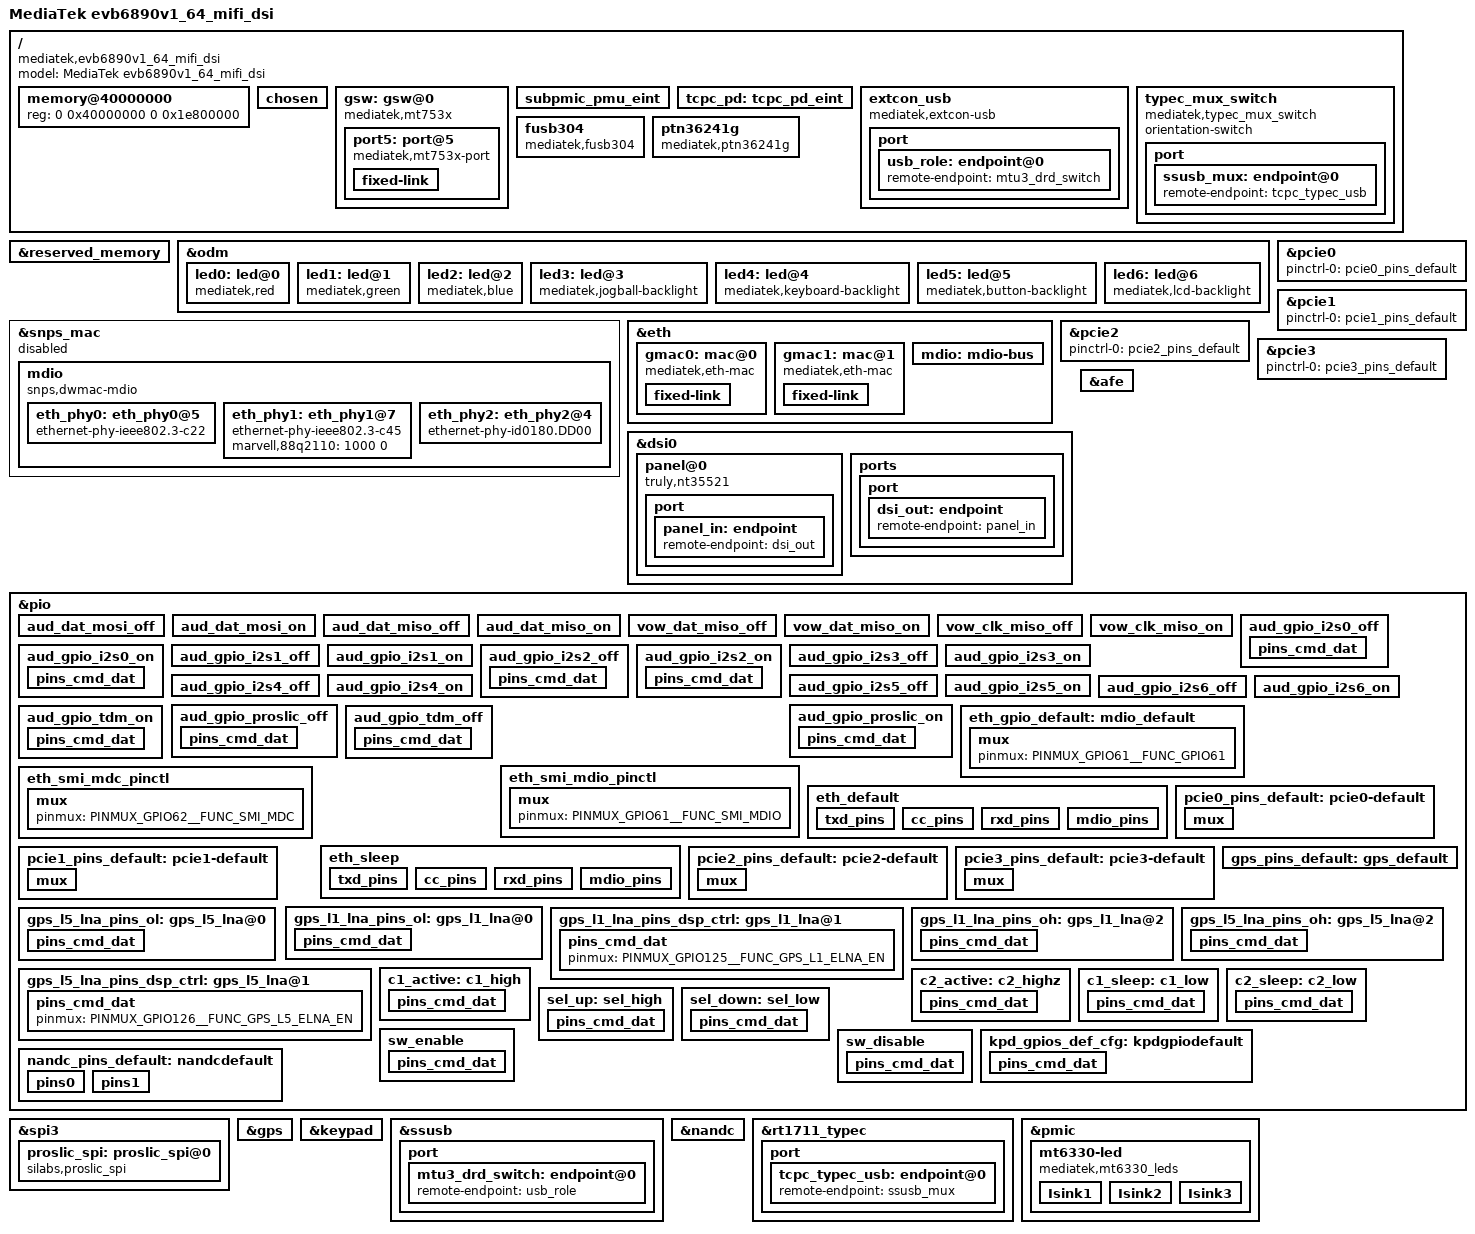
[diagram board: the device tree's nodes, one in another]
// SPDX-License-Identifier: GPL-2.0
/*
 * Copyright (c) 2019 MediaTek Inc.
 */

/dts-v1/;
#include <dt-bindings/interrupt-controller/irq.h>
#include <dt-bindings/interrupt-controller/arm-gic.h>
#include "mt6890.dtsi"
#include "tcpc_config.dtsi"
#include "rt9467.dtsi"

&reserved_memory {
};

/ {
	model = "MediaTek evb6890v1_64_mifi_dsi";
	compatible = "mediatek,evb6890v1_64_mifi_dsi", "mediatek,mt6890";

	memory@40000000 {
		device_type = "memory";
		reg = <0 0x40000000 0 0x1e800000>;
	};

	chosen {
		bootargs = "console=tty0 console=ttyS0,921600n1 \
		root=/dev/ubiblock0_0 rootfstype=squashfs ubi.mtd=28 \
		init=/etc/preinit \
		loglevel=8 \
		androidboot.selinux=permissive androidboot.hardware=mt6890 \
		initcall_debug=1 page_owner=on";

		atag,videolfb-fb_base_l = <0x7e605000>;
		atag,videolfb-fb_base_h = <0x0>;
		atag,videolfb-islcmfound = <1>;
		atag,videolfb-islcm_inited = <0>;
		atag,videolfb-fps= <6000>;
		atag,videolfb-vramSize= <0x1be0000>;
		atag,videolfb-lcmname=
			"nt35595_fhd_dsi_cmd_truly_nt50358_drv";
	};

	gsw: gsw@0 {
		compatible = "mediatek,mt753x";
		mediatek,ethsys = <&ethsys>;
		#address-cells = <1>;
		#size-cells = <0>;
	};

	subpmic_pmu_eint: subpmic_pmu_eint {
	};

	tcpc_pd: tcpc_pd_eint {
	};

    extcon_usb: extcon_usb {
		compatible = "mediatek,extcon-usb";
		vbus-supply = <&otg_vbus>;
		vbus-volt = <5000000>;
		charger = <&rt9467_chg>;
		/*mediatek,bypss-typec-sink = <1>;*/
		vbus-current = <1800000>;
		port {
			usb_role: endpoint@0 {
				remote-endpoint = <&mtu3_drd_switch>;
			};
		};
	};

    typec_mux_switch: typec_mux_switch {
		compatible = "mediatek,typec_mux_switch";
		status = "okay";
		orientation-switch;
		port {
			ssusb_mux: endpoint@0 {
				remote-endpoint = <&tcpc_typec_usb>;
			};
		};
	};

    fusb304: fusb304 {
        compatible = "mediatek,fusb304";
        pinctrl-names = "sel_up", "sel_down",
            "enable", "disable";
        pinctrl-0 = <&sel_up>;
        pinctrl-1 = <&sel_down>;
        pinctrl-2 = <&sw_enable>;
        pinctrl-3 = <&sw_disable>;
        status = "okay";
    };

    ptn36241g: ptn36241g {
        compatible = "mediatek,ptn36241g";
        pinctrl-names = "c1_active", "c1_sleep",
            "c2_active", "c2_sleep";
        pinctrl-0 = <&c1_active>;
        pinctrl-1 = <&c1_sleep>;
        pinctrl-2 = <&c2_active>;
        pinctrl-3 = <&c2_sleep>;
        status = "okay";
    };
};

&odm {
    led0:led@0 {
        compatible = "mediatek,red";
        led_mode = <0>;
        data = <1>;
        pwm_config = <0 0 0 0 0>;
    };
    led1:led@1 {
        compatible = "mediatek,green";
        led_mode = <0>;
        data = <1>;
        pwm_config = <0 0 0 0 0>;
    };
    led2:led@2 {
        compatible = "mediatek,blue";
        led_mode = <0>;
        data = <1>;
        pwm_config = <0 0 0 0 0>;
    };
    led3:led@3 {
        compatible = "mediatek,jogball-backlight";
        led_mode = <0>;
        data = <1>;
        pwm_config = <0 0 0 0 0>;
    };
    led4:led@4 {
        compatible = "mediatek,keyboard-backlight";
        led_mode = <0>;
        data = <1>;
        pwm_config = <0 0 0 0 0>;
    };
    led5:led@5 {
        compatible = "mediatek,button-backlight";
        led_mode = <0>;
        data = <1>;
        pwm_config = <0 0 0 0 0>;
    };
    led6:led@6 {
        compatible = "mediatek,lcd-backlight";
        led_mode = <5>;
        data = <1>;
        pwm_config = <0 1 0 0 0>;
    };
};

&snps_mac {
	phy-mode ="rgmii-rxid";
	phy-handle = <&eth_phy0>;
	status = "disable";
	pinctrl-names = "default", "sleep";
	pinctrl-0 = <&eth_default>;
	pinctrl-1 = <&eth_sleep>;
	snps,reset-gpio = <&pio 24 GPIO_ACTIVE_LOW>;
	snps,reset-active-low;
	mdio {
		compatible = "snps,dwmac-mdio";
		#address-cells = <1>;
		#size-cells = <0>;
		eth_phy0: eth_phy0@5 {
			compatible = "ethernet-phy-ieee802.3-c22";
		};
		eth_phy1: eth_phy1@7 {
			compatible = "ethernet-phy-ieee802.3-c45";
			marvell,88q2110 = <1000 0>;
		};
		eth_phy2: eth_phy2@4 {
			compatible = "ethernet-phy-id0180.DD00";
		};
	};
};


&eth {
	pinctrl-names = "eth_gpio_default",
		"eth_smi_mdio_pinctl",
		"eth_smi_mdc_pinctl";
	pinctrl-0 = <&eth_gpio_default>;
	pinctrl-1 = <&eth_smi_mdio_pinctl>;
	pinctrl-2 = <&eth_smi_mdc_pinctl>;
	status = "okay";
	gmac0: mac@0 {
		compatible = "mediatek,eth-mac";
		reg = <0>;
		phy-mode = "2500base-x";
		fixed-link {
			speed = <2500>;
			full-duplex;
			pause;
		};
	};
	gmac1: mac@1 {
		compatible = "mediatek,eth-mac";
		reg = <1>;
		phy-mode = "2500base-x";
		fixed-link {
			speed = <2500>;
			full-duplex;
			pause;
		};
	};
	mdio: mdio-bus {
		#address-cells = <1>;
		#size-cells = <0>;
	};
};

&gsw {
	mediatek,mdio = <&mdio>;
	mediatek,portmap = "llllw";
	mediatek,mdio_master_pinmux = <0>;
	reset-gpios = <&pio 66 0>;
	interrupt-parent = <&pio>;
	interrupts = <65 IRQ_TYPE_LEVEL_HIGH>;

	status = "okay";

	port5: port@5 {
		compatible = "mediatek,mt753x-port";
		reg = <5>;
		phy-mode = "sgmii";
		fixed-link {
			speed = <2500>;
			full-duplex;
		};
	};
};

&pcie0 {
	pinctrl-names = "default";
	pinctrl-0 = <&pcie0_pins_default>;
	status = "okay";
};

&pcie1 {
	pinctrl-names = "default";
	pinctrl-0 = <&pcie1_pins_default>;
	status = "okay";
};

&pcie2 {
	pinctrl-names = "default";
	pinctrl-0 = <&pcie2_pins_default>;
	status = "okay";
};

&pcie3 {
	pinctrl-names = "default";
	pinctrl-0 = <&pcie3_pins_default>;
	status = "okay";
};

/*
&odm {
	vibrator0:vibrator@0 {
		compatible = "mediatek,vibrator";
		vib_timer = <25>;
		vib_limit = <9>;
		vib_vol= <9>;
	};
};*/

&dsi0 {
	status = "okay";
	#address-cells = <1>;
	#size-cells = <0>;
	panel@0 {
		compatible = "truly,nt35521";
		reg = <0>;
		pm-enable-gpios = <&pio 8 0>;
		reset-gpios = <&pio 208 0>;
		bias-gpios = <&pio 10 0>,
			<&pio 10 0>;
		pinctrl-names = "default";
		port {
			panel_in: endpoint {
				remote-endpoint = <&dsi_out>;
			};
		};
	};
	ports {
		port {
			dsi_out: endpoint {
				remote-endpoint = <&panel_in>;
			};
		};
	};
};

/* AUDIO GPIO standardization */
&afe {
	pinctrl-names = "aud_dat_miso_off", "aud_dat_miso_on",
			"aud_dat_mosi_off", "aud_dat_mosi_on",
			"aud_gpio_i2s0_off", "aud_gpio_i2s0_on",
			"aud_gpio_i2s1_off", "aud_gpio_i2s1_on",
			"aud_gpio_i2s2_off", "aud_gpio_i2s2_on",
			"aud_gpio_i2s3_off", "aud_gpio_i2s3_on",
			"aud_gpio_i2s4_off", "aud_gpio_i2s4_on",
			"aud_gpio_i2s5_off", "aud_gpio_i2s5_on",
			"aud_gpio_i2s6_off", "aud_gpio_i2s6_on",
			"vow_dat_miso_off", "vow_dat_miso_on",
			"vow_clk_miso_off", "vow_clk_miso_on",
			"aud_gpio_proslic_off", "aud_gpio_proslic_on",
			"aud_gpio_tdm_off", "aud_gpio_tdm_on";
	pinctrl-0 = <&aud_dat_mosi_off>;
	pinctrl-1 = <&aud_dat_mosi_on>;
	pinctrl-2 = <&aud_dat_miso_off>;
	pinctrl-3 = <&aud_dat_miso_on>;
	pinctrl-4 = <&aud_gpio_i2s0_off>;
	pinctrl-5 = <&aud_gpio_i2s0_on>;
	pinctrl-6 = <&aud_gpio_i2s1_off>;
	pinctrl-7 = <&aud_gpio_i2s1_on>;
	pinctrl-8 = <&aud_gpio_i2s2_off>;
	pinctrl-9 = <&aud_gpio_i2s2_on>;
	pinctrl-10 = <&aud_gpio_i2s3_off>;
	pinctrl-11 = <&aud_gpio_i2s3_on>;
	pinctrl-12 = <&aud_gpio_i2s4_off>;
	pinctrl-13 = <&aud_gpio_i2s4_on>;
	pinctrl-14 = <&aud_gpio_i2s5_off>;
	pinctrl-15 = <&aud_gpio_i2s5_on>;
	pinctrl-16 = <&aud_gpio_i2s6_off>;
	pinctrl-17 = <&aud_gpio_i2s6_on>;
	pinctrl-18 = <&vow_dat_miso_off>;
	pinctrl-19 = <&vow_dat_miso_on>;
	pinctrl-20 = <&vow_clk_miso_off>;
	pinctrl-21 = <&vow_clk_miso_on>;
	pinctrl-22 = <&aud_gpio_proslic_off>;
	pinctrl-23 = <&aud_gpio_proslic_on>;
	pinctrl-24 = <&aud_gpio_tdm_off>;
	pinctrl-25 = <&aud_gpio_tdm_on>;
	status = "okay";
};

&pio {
	/* set audio pinctrl status */
	aud_dat_mosi_off: aud_dat_mosi_off {
	};
	aud_dat_mosi_on: aud_dat_mosi_on {
	};
	aud_dat_miso_off: aud_dat_miso_off {
	};
	aud_dat_miso_on: aud_dat_miso_on {
	};
	vow_dat_miso_off: vow_dat_miso_off {
	};
	vow_dat_miso_on: vow_dat_miso_on {
	};
	vow_clk_miso_off: vow_clk_miso_off {
	};
	vow_clk_miso_on: vow_clk_miso_on {
	};
	aud_gpio_i2s0_off: aud_gpio_i2s0_off {
		pins_cmd_dat {
			pinmux = <PINMUX_GPIO230__FUNC_GPIO230>,
				 <PINMUX_GPIO231__FUNC_GPIO231>,
				 <PINMUX_GPIO232__FUNC_GPIO232>,
				 <PINMUX_GPIO233__FUNC_GPIO233>,
				 <PINMUX_GPIO234__FUNC_GPIO234>;
		};
	};
	aud_gpio_i2s0_on: aud_gpio_i2s0_on {
		pins_cmd_dat {
			pinmux = <PINMUX_GPIO230__FUNC_I2S0_MCK>,
				 <PINMUX_GPIO231__FUNC_I2S0_BCK>,
				 <PINMUX_GPIO232__FUNC_I2S0_LRCK>,
				 <PINMUX_GPIO233__FUNC_I2S0_DI>,
				 <PINMUX_GPIO234__FUNC_I2S0_DO>;
		};
	};
	aud_gpio_i2s1_off: aud_gpio_i2s1_off {
	};
	aud_gpio_i2s1_on: aud_gpio_i2s1_on {
	};
	aud_gpio_i2s2_off: aud_gpio_i2s2_off {
		pins_cmd_dat {
			pinmux = <PINMUX_GPIO91__FUNC_GPIO91>,
				 <PINMUX_GPIO92__FUNC_GPIO92>,
				 <PINMUX_GPIO93__FUNC_GPIO93>,
				 <PINMUX_GPIO94__FUNC_GPIO94>;
		};
	};
	aud_gpio_i2s2_on: aud_gpio_i2s2_on {
		pins_cmd_dat {
			pinmux = <PINMUX_GPIO91__FUNC_I2S2_MCK>,
				 <PINMUX_GPIO92__FUNC_I2S2_BCK>,
				 <PINMUX_GPIO93__FUNC_I2S2_LRCK>,
				 <PINMUX_GPIO94__FUNC_I2S2_DI>;
		};
	};
	aud_gpio_i2s3_off: aud_gpio_i2s3_off {
	};
	aud_gpio_i2s3_on: aud_gpio_i2s3_on {
	};
	aud_gpio_i2s4_off: aud_gpio_i2s4_off {
	};
	aud_gpio_i2s4_on: aud_gpio_i2s4_on {
	};
	aud_gpio_i2s5_off: aud_gpio_i2s5_off {
	};
	aud_gpio_i2s5_on: aud_gpio_i2s5_on {
	};
	aud_gpio_i2s6_off: aud_gpio_i2s6_off {
	};
	aud_gpio_i2s6_on: aud_gpio_i2s6_on {
	};

	aud_gpio_proslic_off: aud_gpio_proslic_off {
		pins_cmd_dat {
			pinmux = <PINMUX_GPIO231__FUNC_GPIO231>,
				 <PINMUX_GPIO232__FUNC_GPIO232>,
				 <PINMUX_GPIO233__FUNC_GPIO233>,
				 <PINMUX_GPIO234__FUNC_GPIO234>;
		};
	};
	aud_gpio_proslic_on: aud_gpio_proslic_on {
		pins_cmd_dat {
			pinmux = <PINMUX_GPIO231__FUNC_PCM1_CLK>,
				 <PINMUX_GPIO232__FUNC_PCM1_SYNC>,
				 <PINMUX_GPIO233__FUNC_PCM1_DI>,
				 <PINMUX_GPIO234__FUNC_PCM1_DO>;
		};
	};
	aud_gpio_tdm_off: aud_gpio_tdm_off {
		pins_cmd_dat {
			pinmux = <PINMUX_GPIO199__FUNC_GPIO199>,
				 <PINMUX_GPIO200__FUNC_GPIO200>,
				 <PINMUX_GPIO201__FUNC_GPIO201>,
				 <PINMUX_GPIO202__FUNC_GPIO202>,
				 <PINMUX_GPIO203__FUNC_GPIO203>,
				 <PINMUX_GPIO204__FUNC_GPIO204>,
				 <PINMUX_GPIO205__FUNC_GPIO205>;
		};
	};
	aud_gpio_tdm_on: aud_gpio_tdm_on {
		pins_cmd_dat {
			pinmux = <PINMUX_GPIO199__FUNC_TDM_LRCK>,
				 <PINMUX_GPIO200__FUNC_TDM_BCK>,
				 <PINMUX_GPIO201__FUNC_TDM_MCK>,
				 <PINMUX_GPIO202__FUNC_TDM_DATA0>,
				 <PINMUX_GPIO203__FUNC_TDM_DATA1>,
				 <PINMUX_GPIO204__FUNC_TDM_DATA2>,
				 <PINMUX_GPIO205__FUNC_TDM_DATA3>;
		};
	};
};
/* AUDIO GPIO standardization end */

/* DISPSYS GPIO standardization */
#if 0
&pio {
	mtkfb_pins_lcd_bias_enp1: lcd_bias_enp1_gpio {
		pins_cmd_dat {
			pinmux = <PINMUX_GPIO28__FUNC_GPIO28>;
			slew-rate = <1>;
			output-high;
		};
	};

	mtkfb_pins_lcd_bias_enp0: lcd_bias_enp0_gpio {
		pins_cmd_dat {
			pinmux = <PINMUX_GPIO28__FUNC_GPIO28>;
			slew-rate = <1>;
			output-low;
		};
	};

	mtkfb_pins_lcd_bias_enn1: lcd_bias_enn1_gpio {
		pins_cmd_dat {
			pinmux = <PINMUX_GPIO29__FUNC_GPIO29>;
			slew-rate = <1>;
			output-high;
		};
	};

	mtkfb_pins_lcd_bias_enn0: lcd_bias_enn0_gpio {
		pins_cmd_dat {
			pinmux = <PINMUX_GPIO29__FUNC_GPIO29>;
			slew-rate = <1>;
			output-low;
		};
	};

	mtkfb_pins_lcm_rst_out1_gpio: lcm_rst_out1_gpio {
		pins_cmd_dat {
			pinmux = <PINMUX_GPIO42__FUNC_GPIO42>;
			slew-rate = <1>;
			output-high;
		};
	};

	mtkfb_pins_lcm_rst_out0_gpio: lcm_rst_out0_gpio {
		pins_cmd_dat {
			pinmux = <PINMUX_GPIO42__FUNC_GPIO42>;
			slew-rate = <1>;
			output-low;
		};
	};
	mtkfb_pins_lcm_dsi_te: lcm_dsi_te {
		pins_cmd_dat {
			pinmux = <PINMUX_GPIO41__FUNC_DSI_TE>;
		};
	};
};

&mtkfb {
	pinctrl-names = "lcd_bias_enp1_gpio", "lcd_bias_enp0_gpio",
		"lcd_bias_enn1_gpio", "lcd_bias_enn0_gpio",
		"lcm_rst_out1_gpio", "lcm_rst_out0_gpio",
		"mode_te_te";
	pinctrl-0 = <&mtkfb_pins_lcd_bias_enp1>;
	pinctrl-1 = <&mtkfb_pins_lcd_bias_enp0>;
	pinctrl-2 = <&mtkfb_pins_lcd_bias_enn1>;
	pinctrl-3 = <&mtkfb_pins_lcd_bias_enn0>;
	pinctrl-4 = <&mtkfb_pins_lcm_rst_out1_gpio>;
	pinctrl-5 = <&mtkfb_pins_lcm_rst_out0_gpio>;
	pinctrl-6 = <&mtkfb_pins_lcm_dsi_te>;
	status = "okay";
};
#endif

&spi3 {
	status = "okay";
	#address-cells=<1>;
	#size-cells=<0>;

	proslic_spi: proslic_spi@0 {
		compatible = "silabs,proslic_spi";
		#sound-dai-cells = <0>;
		reg = <0>;
		spi-max-frequency = <24000000>;
		spi-cpha = <1>;
		spi-cpol = <1>;
		channel_count = <1>;
		debug_level = <7>;       /* 1 = TRC, 2 = DBG, 4 = ERR */
		reset_gpio = <&pio 23 0>;       /* Hz */
		ig,enable-spi = <1>;                /* 1: Enable, 0: Disable */
	};
};

/* GPS GPIO standardization start */
#if 1
&pio {

	eth_gpio_default: mdio_default {
		mux {
			pinmux = <PINMUX_GPIO61__FUNC_GPIO61>;
		};
	};

	eth_smi_mdio_pinctl: eth_smi_mdio_pinctl {
		mux {
			pinmux = <PINMUX_GPIO61__FUNC_SMI_MDIO>;
		};
	};

	eth_smi_mdc_pinctl: eth_smi_mdc_pinctl {
		mux {
			pinmux = <PINMUX_GPIO62__FUNC_SMI_MDC>;
		};
	};

	eth_default: eth_default {
		txd_pins {
			pinmux = <PINMUX_GPIO8__FUNC_GBE_TXD3>,
				 <PINMUX_GPIO9__FUNC_GBE_TXD2>,
				 <PINMUX_GPIO10__FUNC_GBE_TXD1>,
				 <PINMUX_GPIO11__FUNC_GBE_TXD0>;
			drive-strength = <MTK_DRIVE_8mA>;
		};
		cc_pins {
			pinmux = <PINMUX_GPIO18__FUNC_GBE_TXC>,
				 <PINMUX_GPIO21__FUNC_GBE_TXEN>,
				 <PINMUX_GPIO20__FUNC_GBE_RXDV>,
				 <PINMUX_GPIO19__FUNC_GBE_RXC>;
			drive-strength = <MTK_DRIVE_8mA>;
		};
		rxd_pins {
			pinmux = <PINMUX_GPIO14__FUNC_GBE_RXD3>,
				 <PINMUX_GPIO15__FUNC_GBE_RXD2>,
				 <PINMUX_GPIO16__FUNC_GBE_RXD1>,
				 <PINMUX_GPIO17__FUNC_GBE_RXD0>;
		};
		mdio_pins {
			pinmux = <PINMUX_GPIO12__FUNC_GBE_MDC>,
				 <PINMUX_GPIO13__FUNC_GBE_MDIO>;
			input-enable;
		};
	};

	eth_sleep: eth_sleep {
		txd_pins {
			pinmux = <PINMUX_GPIO8__FUNC_GPIO8>,
				 <PINMUX_GPIO9__FUNC_GPIO9>,
				 <PINMUX_GPIO10__FUNC_GPIO10>,
				 <PINMUX_GPIO11__FUNC_GPIO11>;
		};
		cc_pins {
			pinmux = <PINMUX_GPIO18__FUNC_GPIO18>,
				 <PINMUX_GPIO21__FUNC_GPIO21>,
				 <PINMUX_GPIO20__FUNC_GPIO20>,
				 <PINMUX_GPIO19__FUNC_GPIO19>;
		};
		rxd_pins {
			pinmux = <PINMUX_GPIO14__FUNC_GPIO14>,
				 <PINMUX_GPIO15__FUNC_GPIO15>,
				 <PINMUX_GPIO16__FUNC_GPIO16>,
				 <PINMUX_GPIO17__FUNC_GPIO17>;
		};
		mdio_pins {
			pinmux = <PINMUX_GPIO12__FUNC_GPIO12>,
				 <PINMUX_GPIO13__FUNC_GPIO13>;
			input-disable;
			bias-disable;
		};
	};

	pcie0_pins_default: pcie0-default {
		mux {
			pinmux = <PINMUX_GPIO67__FUNC_PCIE_PERESET_N_0P>,
			         <PINMUX_GPIO68__FUNC_PCIE_WAKE_N_0P>,
				 <PINMUX_GPIO69__FUNC_PCIE_CLKREQ_N_0P>;
			bias-pull-up;
		};
	};

	pcie1_pins_default: pcie1-default {
		mux {
			pinmux = <PINMUX_GPIO70__FUNC_PCIE_PERESET_N_1P>,
			         <PINMUX_GPIO71__FUNC_PCIE_WAKE_N_1P>,
				 <PINMUX_GPIO72__FUNC_PCIE_CLKREQ_N_1P>;
			bias-pull-up;
		};
	};

	pcie2_pins_default: pcie2-default {
		mux {
			pinmux = <PINMUX_GPIO73__FUNC_PCIE_PERESET_N_2P>,
			         <PINMUX_GPIO74__FUNC_PCIE_WAKE_N_2P>,
				 <PINMUX_GPIO75__FUNC_PCIE_CLKREQ_N_2P>;
			bias-pull-up;
		};
	};

	pcie3_pins_default: pcie3-default {
		mux {
			pinmux = <PINMUX_GPIO76__FUNC_PCIE_PERESET_N_3P>,
			         <PINMUX_GPIO77__FUNC_PCIE_WAKE_N_3P>,
				 <PINMUX_GPIO78__FUNC_PCIE_CLKREQ_N_3P>;
			bias-pull-up;
		};
	};

	gps_pins_default: gps_default {
	};

	gps_l1_lna_pins_ol: gps_l1_lna@0 {
		pins_cmd_dat {
			pinmux = <PINMUX_GPIO125__FUNC_GPIO125>;
			output-low;
		};
	};
	gps_l1_lna_pins_dsp_ctrl: gps_l1_lna@1 {
		pins_cmd_dat {
			pinmux = <PINMUX_GPIO125__FUNC_GPS_L1_ELNA_EN>;
		};
	};
	gps_l1_lna_pins_oh: gps_l1_lna@2 {
		pins_cmd_dat {
			pinmux = <PINMUX_GPIO125__FUNC_GPIO125>;
			output-high;
		};
	};

	gps_l5_lna_pins_ol: gps_l5_lna@0 {
		pins_cmd_dat {
			pinmux = <PINMUX_GPIO126__FUNC_GPIO126>;
			output-low;
		};
	};
	gps_l5_lna_pins_dsp_ctrl: gps_l5_lna@1 {
		pins_cmd_dat {
			pinmux = <PINMUX_GPIO126__FUNC_GPS_L5_ELNA_EN>;
		};
	};
	gps_l5_lna_pins_oh: gps_l5_lna@2 {
		pins_cmd_dat {
			pinmux = <PINMUX_GPIO126__FUNC_GPIO126>;
			output-high;
		};
	};
};

&gps {
	pinctrl-names = "default",
		"gps_l1_lna_disable",
		"gps_l1_lna_dsp_ctrl",
		"gps_l1_lna_enable",
		"gps_l5_lna_disable",
		"gps_l5_lna_dsp_ctrl",
		"gps_l5_lna_enable";
	pinctrl-0 = <&gps_pins_default>;
	pinctrl-1 = <&gps_l1_lna_pins_ol>;
	pinctrl-2 = <&gps_l1_lna_pins_dsp_ctrl>;
	pinctrl-3 = <&gps_l1_lna_pins_oh>;
	pinctrl-4 = <&gps_l5_lna_pins_ol>;
	pinctrl-5 = <&gps_l5_lna_pins_dsp_ctrl>;
	pinctrl-6 = <&gps_l5_lna_pins_oh>;
	status = "okay";
};
#endif
/* GPS GPIO standardization end */

/* usb typec swtich */
&pio {
	c1_active: c1_high {
		pins_cmd_dat {
			pinmux = <PINMUX_GPIO95__FUNC_GPIO95>;
			output-high;
		};
	};

	c2_active: c2_highz {
		pins_cmd_dat {
			pinmux = <PINMUX_GPIO94__FUNC_GPIO94>;
			input-enable;
			bias-disable;
		};
	};

	c1_sleep: c1_low {
		pins_cmd_dat {
			pinmux = <PINMUX_GPIO95__FUNC_GPIO95>;
			output-low;
		};
	};

	c2_sleep: c2_low {
		pins_cmd_dat {
			pinmux = <PINMUX_GPIO94__FUNC_GPIO94>;
			output-low;
		};
	};

	sel_up: sel_high {
		pins_cmd_dat {
			pinmux = <PINMUX_GPIO93__FUNC_GPIO93>;
			output-high;
		};
	};

	sel_down: sel_low {
		pins_cmd_dat {
			pinmux = <PINMUX_GPIO93__FUNC_GPIO93>;
			output-low;
		};
	};

	sw_enable: sw_enable {
		pins_cmd_dat {
			pinmux = <PINMUX_GPIO92__FUNC_GPIO92>;
			output-low;
		};
	};

	sw_disable: sw_disable {
		pins_cmd_dat {
			pinmux = <PINMUX_GPIO92__FUNC_GPIO92>;
			output-low;
		};
	};
	kpd_gpios_def_cfg: kpdgpiodefault {
		pins_cmd_dat {
			pinmux = <PINMUX_GPIO114__FUNC_KPROW0>,
				<PINMUX_GPIO115__FUNC_KPROW1>;
			mediatek,pull-down-adv = <MTK_PUPD_SET_R1R0_01>;
			output-low;
			input-schmitt-enable;
		};
	};
};

&keypad {
	mediatek,key-debounce-ms = <1024>;
	/*HW Keycode [0~71] -> Linux Keycode*/
	mediatek,hw-map-num = <72>;
	mediatek,hw-init-map = <0 0 114 0 0 0 0 0 0 0 0 0 0 0 0 115 0 0 0 0 0 0 0
		0 0 0 0 0 112 0 0 0 0 0 0 0 0 0 0 0 0 0 0 0 0 0 0 0 0 0 0 0 0 0 0
		0 0 0 0 0 0 0 0 0 0 0 0 0 0 0 0 0 >;
	status = "okay";
	pinctrl-names = "default";
	pinctrl-0 = <&kpd_gpios_def_cfg>;
};

&ssusb {
	port {
		mtu3_drd_switch: endpoint@0 {
			remote-endpoint = <&usb_role>;
		};
	};
};

&pio {
	nandc_pins_default: nandcdefault {
		pins0 {
			pinmux = <PINMUX_GPIO215__FUNC_NLD0>,
				<PINMUX_GPIO216__FUNC_NLD1>,
				<PINMUX_GPIO217__FUNC_NLD2>,
				<PINMUX_GPIO218__FUNC_NLD3>,
				<PINMUX_GPIO219__FUNC_NLD4>,
				<PINMUX_GPIO220__FUNC_NLD5>,
				<PINMUX_GPIO221__FUNC_NLD6>,
				<PINMUX_GPIO222__FUNC_NLD7>,
				<PINMUX_GPIO228__FUNC_NALE>,
				<PINMUX_GPIO229__FUNC_NCLE>;
			drive-strength = <MTK_DRIVE_4mA>;
			bias-pull-down;
		};
		pins1 {
			pinmux = <PINMUX_GPIO223__FUNC_NCEB1>,
				<PINMUX_GPIO224__FUNC_NCEB0>,
				<PINMUX_GPIO225__FUNC_NRNB>,
				<PINMUX_GPIO226__FUNC_NREB>,
				<PINMUX_GPIO227__FUNC_NWEB>;
			drive-strength = <MTK_DRIVE_4mA>;
			bias-pull-up;
		};
	};
};

&nandc {
	status = "okay";
	pinctrl-names = "default";
	pinctrl-0 = <&nandc_pins_default>;
	clocks =<&topckgen_clk CLK_TOP_TCK_26M_MX9>,
			<&topckgen_clk CLK_TOP_UNIVPLL_D5_D4>,
			<&topckgen_clk CLK_TOP_MAINPLL_D7_D4>,
			<&topckgen_clk CLK_TOP_MAINPLL_D6_D4>,
			<&topckgen_clk CLK_TOP_UNIVPLL_D6_D4>,
			<&topckgen_clk CLK_TOP_MAINPLL_D4_D4>,
			<&topckgen_clk CLK_TOP_UNIVPLL_D4_D4>,
			<&topckgen_clk CLK_TOP_MAINPLL_D6_D2>,
			<&topckgen_clk CLK_TOP_NFI1X_SEL>,
			<&infracfg_ao_clk CLK_IFRAO_RG_66M_NFI_HCLK_CK>,
			<&infracfg_ao_clk CLK_IFRAO_RG_NFI>;
	clock-names = "nfi_parent_26m",
			"nfi_parent124.8m",
			"nfi_parent78m",
			"nfi_parent91m",
			"nfi_parent104m",
			"nfi_parent136.5m",
			"nfi_parent156m",
			"nfi_parent182m",
			"nfi_clk_sel",
			"dma_cg",
			"nfi_cg";
};

&rt1711_typec {
    port {
	tcpc_typec_usb: endpoint@0 {
	    remote-endpoint = <&ssusb_mux>;
	};
    };
};

/*************************
 * PMIC LED DTSI File
*************************/
&pmic {
	mt6330-led {
		compatible = "mediatek,mt6330_leds";
		Isink1 {
			reg = <1>;
			label = "led9515:green:pmic";
			linux,default-trigger = "none";
			default-state = "off";
		};
		Isink2 {
			reg = <2>;
			label = "led9516:green:pmic";
			linux,default-trigger = "none";
			default-state = "off";
		};
		Isink3 {
			reg = <3>;
			label = "led9517:red:system";
			linux,default-trigger = "none";
			default-state = "off";
		};
	};
};

#include <mediatek/evb6890v1_64_mifi_dsi/cust.dtsi>
/*End of this file, DO NOT ADD ANYTHING HERE*/
